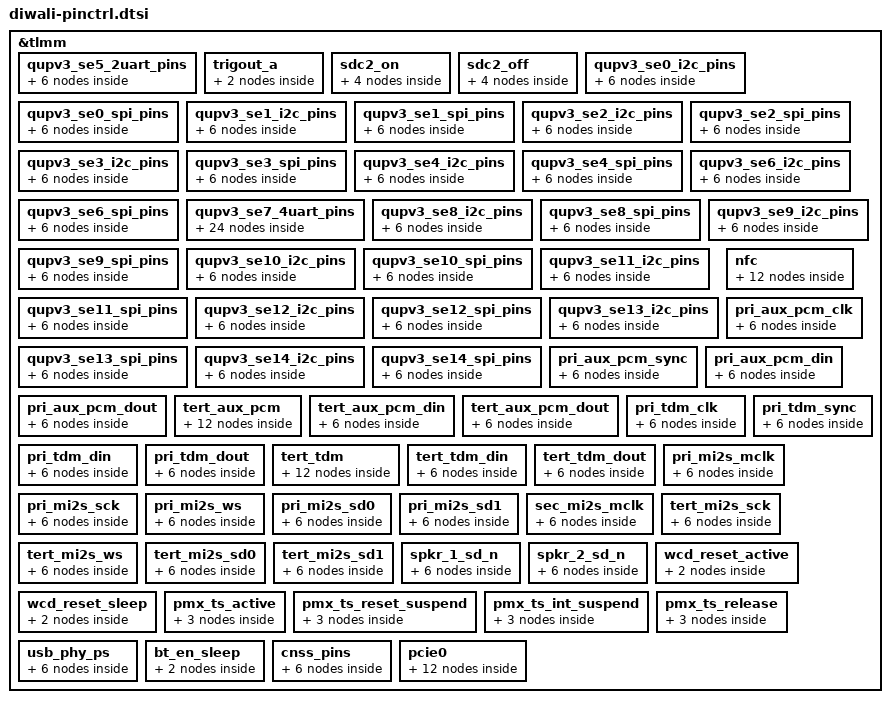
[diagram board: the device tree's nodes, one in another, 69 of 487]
&tlmm {
	qupv3_se5_2uart_pins: qupv3_se5_2uart_pins {
		qupv3_se5_2uart_active: qupv3_se5_2uart_active {
			mux {
				pins = "gpio22", "gpio23";
				function = "qup0_se5";
			};

			config {
				pins = "gpio22", "gpio23";
				drive-strength = <2>;
				bias-disable;
			};
		};

	qupv3_se5_2uart_sleep: qupv3_se5_2uart_sleep {
			mux {
				pins = "gpio22", "gpio23";
				function = "gpio";
			};

			config {
				pins = "gpio22", "gpio23";
				drive-strength = <2>;
				bias-pull-down;
			};
		};
	};

	trigout_a: trigout_a {
		mux {
			pins = "gpio52";
			function = "qdss_cti";
		};

		config {
			pins = "gpio52";
			drive-strength = <2>;
			bias-disable;
		};
	};

	sdc2_on: sdc2_on {
		clk {
			pins = "sdc2_clk";
			bias-disable;
			drive-strength = <16>;
		};

		cmd {
			pins = "sdc2_cmd";
			bias-pull-up;
			drive-strength = <10>;
		};

		data {
			pins = "sdc2_data";
			bias-pull-up;
			drive-strength = <10>;
		};

		sd-cd {
			pins = "gpio19";
			bias-pull-up;
			drive-strength = <2>;
		};
	};

	sdc2_off: sdc2_off {
		clk {
			pins = "sdc2_clk";
			bias-disable;
			drive-strength = <2>;
		};

		cmd {
			pins = "sdc2_cmd";
			bias-pull-up;
			drive-strength = <2>;
		};

		data {
			pins = "sdc2_data";
			bias-pull-up;
			drive-strength = <2>;
		};

		sd-cd {
			pins = "gpio19";
			bias-pull-up;
			drive-strength = <2>;
		};
	};

	qupv3_se0_i2c_pins: qupv3_se0_i2c_pins {
		qupv3_se0_i2c_active: qupv3_se0_i2c_active {
			mux {
				pins = "gpio0", "gpio1";
				function = "qup0_se0";
			};

			config {
				pins = "gpio0", "gpio1";
				drive-strength = <2>;
				bias-pull-up;
			};
		};

		qupv3_se0_i2c_sleep: qupv3_se0_i2c_sleep {
			mux {
				pins = "gpio0", "gpio1";
				function = "gpio";
			};

			config {
				pins = "gpio0", "gpio1";
				drive-strength = <2>;
				bias-disable;
			};
		};
	};

	qupv3_se0_spi_pins: qupv3_se0_spi_pins {
		qupv3_se0_spi_active: qupv3_se0_spi_active {
			mux {
				pins = "gpio0", "gpio1",
						"gpio2", "gpio3";
				function = "qup0_se0";
			};

			config {
				pins = "gpio0", "gpio1",
						"gpio2", "gpio3";
				drive-strength = <6>;
				bias-disable;
			};
		};

		qupv3_se0_spi_sleep: qupv3_se0_spi_sleep {
			mux {
				pins = "gpio0", "gpio1",
						"gpio2", "gpio3";
				function = "gpio";
			};

			config {
				pins = "gpio0", "gpio1",
						"gpio2", "gpio3";
				drive-strength = <6>;
				bias-disable;
			};
		};
	};

	qupv3_se1_i2c_pins: qupv3_se1_i2c_pins {
		qupv3_se1_i2c_active: qupv3_se1_i2c_active {
			mux {
				pins = "gpio4", "gpio5";
				function = "qup0_se1";
			};

			config {
				pins = "gpio4", "gpio5";
				drive-strength = <2>;
				bias-pull-up;
			};
		};

		qupv3_se1_i2c_sleep: qupv3_se1_i2c_sleep {
			mux {
				pins = "gpio4", "gpio5";
				function = "gpio";
			};

			config {
				pins = "gpio4", "gpio5";
				drive-strength = <2>;
				bias-disable;
			};
		};
	};

	qupv3_se1_spi_pins: qupv3_se1_spi_pins {
		qupv3_se1_spi_active: qupv3_se1_spi_active {
			mux {
				pins = "gpio4", "gpio5",
						"gpio6", "gpio7";
				function = "qup0_se1";
			};

			config {
				pins = "gpio4", "gpio5",
						"gpio6", "gpio7";
				drive-strength = <6>;
				bias-disable;
			};
		};

		qupv3_se1_spi_sleep: qupv3_se1_spi_sleep {
			mux {
				pins = "gpio4", "gpio5",
						"gpio6", "gpio7";
				function = "gpio";
			};

			config {
				pins = "gpio4", "gpio5",
						"gpio6", "gpio7";
				drive-strength = <6>;
				bias-disable;
			};
		};
	};

	qupv3_se2_i2c_pins: qupv3_se2_i2c_pins {
		qupv3_se2_i2c_active: qupv3_se2_i2c_active {
			mux {
				pins = "gpio8", "gpio9";
				function = "qup0_se2";
			};

			config {
				pins = "gpio8", "gpio9";
				drive-strength = <2>;
				bias-pull-up;
			};
		};

		qupv3_se2_i2c_sleep: qupv3_se2_i2c_sleep {
			mux {
				pins = "gpio8", "gpio9";
				function = "gpio";
			};

			config {
				pins = "gpio8", "gpio9";
				drive-strength = <2>;
				bias-disable;
			};
		};
	};

	qupv3_se2_spi_pins: qupv3_se2_spi_pins {
		qupv3_se2_spi_active: qupv3_se2_spi_active {
			mux {
				pins = "gpio8", "gpio9",
						"gpio10", "gpio11";
				function = "qup0_se2";
			};

			config {
				pins = "gpio8", "gpio9",
						"gpio10", "gpio11";
				drive-strength = <6>;
				bias-disable;
			};
		};

		qupv3_se2_spi_sleep: qupv3_se2_spi_sleep {
			mux {
				pins = "gpio8", "gpio9",
						"gpio10", "gpio11";
				function = "gpio";
			};

			config {
				pins = "gpio8", "gpio9",
						"gpio10", "gpio11";
				drive-strength = <6>;
				bias-disable;
			};
		};
	};

	qupv3_se3_i2c_pins: qupv3_se3_i2c_pins {
		qupv3_se3_i2c_active: qupv3_se3_i2c_active {
			mux {
				pins = "gpio12", "gpio13";
				function = "qup0_se3";
			};

			config {
				pins = "gpio12", "gpio13";
				drive-strength = <2>;
				bias-pull-up;
			};
		};

		qupv3_se3_i2c_sleep: qupv3_se3_i2c_sleep {
			mux {
				pins = "gpio12", "gpio13";
				function = "gpio";
			};

			config {
				pins = "gpio12", "gpio13";
				drive-strength = <2>;
				bias-disable;
			};
		};
	};

	qupv3_se3_spi_pins: qupv3_se3_spi_pins {
		qupv3_se3_spi_active: qupv3_se3_spi_active {
			mux {
				pins = "gpio12", "gpio13",
						"gpio14", "gpio15";
				function = "qup0_se3";
			};

			config {
				pins = "gpio12", "gpio13",
						"gpio14", "gpio15";
				drive-strength = <6>;
				bias-disable;
			};
		};

		qupv3_se3_spi_sleep: qupv3_se3_spi_sleep {
			mux {
				pins = "gpio12", "gpio13",
						"gpio14", "gpio15";
				function = "gpio";
			};

			config {
				pins = "gpio12", "gpio13",
						"gpio14", "gpio15";
				drive-strength = <6>;
				bias-disable;
			};
		};
	};

	qupv3_se4_i2c_pins: qupv3_se4_i2c_pins {
		qupv3_se4_i2c_active: qupv3_se4_i2c_active {
			mux {
				pins = "gpio16", "gpio17";
				function = "qup0_se4";
			};

			config {
				pins = "gpio16", "gpio17";
				drive-strength = <2>;
				bias-pull-up;
			};
		};

		qupv3_se4_i2c_sleep: qupv3_se4_i2c_sleep {
			mux {
				pins = "gpio16", "gpio17";
				function = "gpio";
			};

			config {
				pins = "gpio16", "gpio17";
				drive-strength = <2>;
				bias-disable;
			};
		};
	};

	qupv3_se4_spi_pins: qupv3_se4_spi_pins {
		qupv3_se4_spi_active: qupv3_se4_spi_active {
			mux {
				pins = "gpio16", "gpio17",
						"gpio18", "gpio19";
				function = "qup0_se4";
			};

			config {
				pins = "gpio16", "gpio17",
						"gpio18", "gpio19";
				drive-strength = <6>;
				bias-disable;
			};
		};

		qupv3_se4_spi_sleep: qupv3_se4_spi_sleep {
			mux {
				pins = "gpio16", "gpio17",
						"gpio18", "gpio19";
				function = "gpio";
			};

			config {
				pins = "gpio16", "gpio17",
						"gpio18", "gpio19";
				drive-strength = <6>;
				bias-disable;
			};
		};
	};

	qupv3_se6_i2c_pins: qupv3_se6_i2c_pins {
		qupv3_se6_i2c_active: qupv3_se6_i2c_active {
			mux {
				pins = "gpio24", "gpio25";
				function = "qup0_se6";
			};

			config {
				pins = "gpio24", "gpio25";
				drive-strength = <2>;
				bias-pull-up;
			};
		};

		qupv3_se6_i2c_sleep: qupv3_se6_i2c_sleep {
			mux {
				pins = "gpio24", "gpio25";
				function = "gpio";
			};

			config {
				pins = "gpio24", "gpio25";
				drive-strength = <2>;
				bias-disable;
			};
		};
	};

	qupv3_se6_spi_pins: qupv3_se6_spi_pins {
		qupv3_se6_spi_active: qupv3_se6_spi_active {
			mux {
				pins = "gpio24", "gpio25",
						"gpio26", "gpio27";
				function = "qup0_se6";
			};

			config {
				pins = "gpio24", "gpio25",
						"gpio26", "gpio27";
				drive-strength = <6>;
				bias-disable;
			};
		};

		qupv3_se6_spi_sleep: qupv3_se6_spi_sleep {
			mux {
				pins = "gpio24", "gpio25",
						"gpio26", "gpio27";
				function = "gpio";
			};

			config {
				pins = "gpio24", "gpio25",
						"gpio26", "gpio27";
				drive-strength = <6>;
				bias-disable;
			};
		};
	};

	qupv3_se7_4uart_pins: qupv3_se7_4uart_pins {
		qupv3_se7_default_cts:
				qupv3_se7_default_cts {
			mux {
				pins = "gpio28";
				function = "gpio";
			};

			config {
				pins = "gpio28";
				drive-strength = <2>;
				bias-disable;
			};
		};

		qupv3_se7_default_rtsrx:
			qupv3_se7_default_rtsrx {
			mux {
				pins = "gpio29", "gpio31";
				function = "gpio";
			};

			config {
				pins = "gpio29", "gpio31";
				drive-strength = <2>;
				bias-pull-down;
			};
		};

		qupv3_se7_default_tx:
			qupv3_se7_default_tx {
			mux {
				pins = "gpio30";
				function = "gpio";
			};

			config {
				pins = "gpio30";
				drive-strength = <2>;
				bias-pull-up;
			};
		};

		qupv3_se7_cts: qupv3_se7_cts {
			mux {
				pins = "gpio28";
				function = "qup0_se7";
			};

			config {
				pins = "gpio28";
				drive-strength = <2>;
				bias-disable;
			};
		};

		qupv3_se7_rts: qupv3_se7_rts {
			mux {
				pins = "gpio29";
				function = "qup0_se7";
			};

			config {
				pins = "gpio29";
				drive-strength = <2>;
				bias-pull-down;
			};
		};

		qupv3_se7_tx: qupv3_se7_tx {
			mux {
				pins = "gpio30";
				function = "qup0_se7";
			};

			config {
				pins = "gpio30";
				drive-strength = <2>;
				bias-pull-up;
			};
		};

		/* RX to be in gpio mode for sleep config */
		qupv3_se7_rx_wake: qupv3_se7_rx_wake {
			mux {
				pins = "gpio31";
				function = "gpio";
			};

			config {
				pins = "gpio31";
				drive-strength = <2>;
				bias-disable;
			};
		};

		qupv3_se7_rx_active: qupv3_se7_rx_active {
			mux {
				pins = "gpio31";
				function = "qup0_se7";
			};

			config {
				pins = "gpio31";
				drive-strength = <2>;
				bias-disable;
			};
		};
	};

	qupv3_se8_i2c_pins: qupv3_se8_i2c_pins {
		qupv3_se8_i2c_active: qupv3_se8_i2c_active {
			mux {
				pins = "gpio32", "gpio33";
				function = "qup1_se0";
			};

			config {
				pins = "gpio32", "gpio33";
				drive-strength = <2>;
				bias-pull-up;
			};
		};

		qupv3_se8_i2c_sleep: qupv3_se8_i2c_sleep {
			mux {
				pins = "gpio32", "gpio33";
				function = "gpio";
			};

			config {
				pins = "gpio32", "gpio33";
				drive-strength = <2>;
				bias-disable;
			};
		};
	};

	qupv3_se8_spi_pins: qupv3_se8_spi_pins {
		qupv3_se8_spi_active: qupv3_se8_spi_active {
			mux {
				pins = "gpio32", "gpio33",
						"gpio34", "gpio35";
				function = "qup1_se0";
			};

			config {
				pins = "gpio32", "gpio33",
						"gpio34", "gpio35";
				drive-strength = <6>;
				bias-disable;
			};
		};

		qupv3_se8_spi_sleep: qupv3_se8_spi_sleep {
			mux {
				pins = "gpio32", "gpio33",
						"gpio34", "gpio35";
				function = "gpio";
			};

			config {
				pins = "gpio32", "gpio33",
						"gpio34", "gpio35";
				drive-strength = <6>;
				bias-disable;
			};
		};
	};

	qupv3_se9_i2c_pins: qupv3_se9_i2c_pins {
		qupv3_se9_i2c_active: qupv3_se9_i2c_active {
			mux {
				pins = "gpio36", "gpio37";
				function = "qup1_se1";
			};

			config {
				pins = "gpio36", "gpio37";
				drive-strength = <2>;
				bias-pull-up;
			};
		};

		qupv3_se9_i2c_sleep: qupv3_se9_i2c_sleep {
			mux {
				pins = "gpio36", "gpio37";
				function = "gpio";
			};

			config {
				pins = "gpio36", "gpio37";
				drive-strength = <2>;
				bias-disable;
			};
		};
	};

	qupv3_se9_spi_pins: qupv3_se9_spi_pins {
		qupv3_se9_spi_active: qupv3_se9_spi_active {
			mux {
				pins = "gpio36", "gpio37",
						"gpio38", "gpio39";
				function = "qup1_se1";
			};

			config {
				pins = "gpio36", "gpio37",
						"gpio38", "gpio39";
				drive-strength = <6>;
				bias-disable;
			};
		};

		qupv3_se9_spi_sleep: qupv3_se9_spi_sleep {
			mux {
				pins = "gpio36", "gpio37",
						"gpio38", "gpio39";
				function = "gpio";
			};

			config {
				pins = "gpio36", "gpio37",
						"gpio38", "gpio39";
				drive-strength = <6>;
				bias-disable;
			};
		};
	};

	qupv3_se10_i2c_pins: qupv3_se10_i2c_pins {
		qupv3_se10_i2c_active: qupv3_se10_i2c_active {
			mux {
				pins = "gpio40", "gpio41";
				function = "qup1_se2";
			};

			config {
				pins = "gpio40", "gpio41";
				drive-strength = <2>;
				bias-pull-up;
			};
		};

		qupv3_se10_i2c_sleep: qupv3_se10_i2c_sleep {
			mux {
				pins = "gpio40", "gpio41";
				function = "gpio";
			};

			config {
				pins = "gpio40", "gpio41";
				drive-strength = <2>;
				bias-disable;
			};
		};
	};

	qupv3_se10_spi_pins: qupv3_se10_spi_pins {
		qupv3_se10_spi_active: qupv3_se10_spi_active {
			mux {
				pins = "gpio40", "gpio41",
						"gpio42", "gpio43";
				function = "qup1_se2";
			};

			config {
				pins = "gpio40", "gpio41",
						"gpio42", "gpio43";
				drive-strength = <6>;
				bias-disable;
			};
		};

		qupv3_se10_spi_sleep: qupv3_se10_spi_sleep {
			mux {
				pins = "gpio40", "gpio41",
						"gpio42", "gpio43";
				function = "gpio";
			};

			config {
				pins = "gpio40", "gpio41",
						"gpio42", "gpio43";
				drive-strength = <6>;
				bias-disable;
			};
		};
	};

	qupv3_se11_i2c_pins: qupv3_se11_i2c_pins {
		qupv3_se11_i2c_active: qupv3_se11_i2c_active {
			mux {
				pins = "gpio44", "gpio45";
				function = "qup1_se3";
			};

			config {
				pins = "gpio44", "gpio45";
				drive-strength = <2>;
				bias-pull-up;
			};
		};

		qupv3_se11_i2c_sleep: qupv3_se11_i2c_sleep {
			mux {
				pins = "gpio44", "gpio45";
				function = "gpio";
			};

			config {
				pins = "gpio44", "gpio45";
				drive-strength = <2>;
				bias-disable;
			};
		};
	};

	qupv3_se11_spi_pins: qupv3_se11_spi_pins {
		qupv3_se11_spi_active: qupv3_se11_spi_active {
			mux {
				pins = "gpio44", "gpio45",
						"gpio46", "gpio47";
				function = "qup1_se3";
			};

			config {
				pins = "gpio44", "gpio45",
						"gpio46", "gpio47";
				drive-strength = <6>;
				bias-disable;
			};
		};

		qupv3_se11_spi_sleep: qupv3_se11_spi_sleep {
			mux {
				pins = "gpio44", "gpio45",
						"gpio46", "gpio47";
				function = "gpio";
			};

			config {
				pins = "gpio44", "gpio45",
						"gpio46", "gpio47";
				drive-strength = <6>;
				bias-disable;
			};
		};
	};

	qupv3_se12_i2c_pins: qupv3_se12_i2c_pins {
		qupv3_se12_i2c_active: qupv3_se12_i2c_active {
			mux {
				pins = "gpio48", "gpio49";
				function = "qup1_se4";
			};

			config {
				pins = "gpio48", "gpio49";
				drive-strength = <2>;
				bias-pull-up;
			};
		};

		qupv3_se12_i2c_sleep: qupv3_se12_i2c_sleep {
			mux {
				pins = "gpio48", "gpio49";
				function = "gpio";
			};

			config {
				pins = "gpio48", "gpio49";
				drive-strength = <2>;
				bias-disable;
			};
		};
	};

	qupv3_se12_spi_pins: qupv3_se12_spi_pins {
		qupv3_se12_spi_active: qupv3_se12_spi_active {
			mux {
				pins = "gpio48", "gpio49",
						"gpio50", "gpio51";
				function = "qup1_se4";
			};

			config {
				pins = "gpio48", "gpio49",
						"gpio50", "gpio51";
				drive-strength = <6>;
				bias-disable;
			};
		};

		qupv3_se12_spi_sleep: qupv3_se12_spi_sleep {
			mux {
				pins = "gpio48", "gpio49",
						"gpio50", "gpio51";
				function = "gpio";
			};

			config {
				pins = "gpio48", "gpio49",
						"gpio50", "gpio51";
				drive-strength = <6>;
				bias-disable;
			};
		};
	};

	qupv3_se13_i2c_pins: qupv3_se13_i2c_pins {
		qupv3_se13_i2c_active: qupv3_se13_i2c_active {
			mux {
				pins = "gpio52", "gpio53";
				function = "qup1_se5";
			};

			config {
				pins = "gpio52", "gpio53";
				drive-strength = <2>;
				bias-pull-up;
			};
		};

		qupv3_se13_i2c_sleep: qupv3_se13_i2c_sleep {
			mux {
				pins = "gpio52", "gpio53";
				function = "gpio";
			};

			config {
				pins = "gpio52", "gpio53";
				drive-strength = <2>;
				bias-disable;
			};
		};
	};

	qupv3_se13_spi_pins: qupv3_se13_spi_pins {
		qupv3_se13_spi_active: qupv3_se13_spi_active {
			mux {
				pins = "gpio52", "gpio53",
						"gpio54", "gpio55";
				function = "qup1_se5";
			};

			config {
				pins = "gpio52", "gpio53",
						"gpio54", "gpio55";
				drive-strength = <6>;
				bias-disable;
			};
		};

		qupv3_se13_spi_sleep: qupv3_se13_spi_sleep {
			mux {
				pins = "gpio52", "gpio53",
						"gpio54", "gpio55";
				function = "gpio";
			};

			config {
				pins = "gpio52", "gpio53",
						"gpio54", "gpio55";
				drive-strength = <6>;
				bias-disable;
			};
		};
	};

	qupv3_se14_i2c_pins: qupv3_se14_i2c_pins {
		qupv3_se14_i2c_active: qupv3_se14_i2c_active {
			mux {
				pins = "gpio56", "gpio57";
				function = "qup1_se6";
			};

			config {
				pins = "gpio56", "gpio57";
				drive-strength = <2>;
				bias-pull-up;
			};
		};

		qupv3_se14_i2c_sleep: qupv3_se14_i2c_sleep {
			mux {
				pins = "gpio56", "gpio57";
				function = "gpio";
			};

			config {
				pins = "gpio56", "gpio57";
				drive-strength = <2>;
				bias-disable;
			};
		};
	};

	qupv3_se14_spi_pins: qupv3_se14_spi_pins {
		qupv3_se14_spi_active: qupv3_se14_spi_active {
			mux {
				pins = "gpio56", "gpio57",
						"gpio58", "gpio59";
				function = "qup1_se6";
			};

			config {
				pins = "gpio56", "gpio57",
						"gpio58", "gpio59";
				drive-strength = <6>;
				bias-disable;
			};
		};

		qupv3_se14_spi_sleep: qupv3_se14_spi_sleep {
			mux {
				pins = "gpio56", "gpio57",
						"gpio58", "gpio59";
				function = "gpio";
			};

			config {
				pins = "gpio56", "gpio57",
						"gpio58", "gpio59";
				drive-strength = <6>;
				bias-disable;
			};
		};
	};

	nfc {
		nfc_int_active: nfc_int_active {
			/* active state */
			mux {
				/* NFC Read Interrupt */
				pins = "gpio41";
				function = "gpio";
			};

			config {
				pins = "gpio41";
				drive-strength = <2>;
				bias-pull-down;
			};
		};

		nfc_int_suspend: nfc_int_suspend {
		/* sleep state */
			mux {
				/* NFC Read Interrupt */
				pins = "gpio41";
				function = "gpio";
			};

			config {
				pins = "gpio41";
				drive-strength = <2>;
				bias-pull-down;
			};
		};

		nfc_enable_active: nfc_enable_active {
			mux {
				/* Enable, Firmware and Clock request gpios */
				pins = "gpio38", "gpio40", "gpio39";
				function = "gpio";
			};

			config {
				pins = "gpio38", "gpio40", "gpio39";
				drive-strength = <2>;
				bias-disable;
			};
		};

		nfc_enable_suspend: nfc_enable_suspend {
			mux {
				pins = "gpio38", "gpio40", "gpio39";
				function = "gpio";
			};

			config {
				pins = "gpio38", "gpio40", "gpio39";
				drive-strength = <2>;
				bias-disable;
			};
		};
	};

	pri_aux_pcm_clk {
		pri_aux_pcm_clk_sleep: pri_aux_pcm_clk_sleep {
			mux {
				pins = "gpio127";
				function = "gpio";
			};

			config {
				pins = "gpio127";
				drive-strength = <2>;   /* 2 mA */
				bias-pull-down;         /* PULL DOWN */
				input-enable;
			};
		};

		pri_aux_pcm_clk_active: pri_aux_pcm_clk_active {
			mux {
				pins = "gpio127";
				function = "mi2s0_sck";
			};

			config {
				pins = "gpio127";
				drive-strength = <8>;   /* 8 mA */
				bias-disable;           /* NO PULL */
				output-high;
			};
		};
	};

	pri_aux_pcm_sync {
		pri_aux_pcm_sync_sleep: pri_aux_pcm_sync_sleep {
			mux {
				pins = "gpio130";
				function = "gpio";
			};

			config {
				pins = "gpio130";
				drive-strength = <2>;   /* 2 mA */
				bias-pull-down;         /* PULL DOWN */
				input-enable;
			};
		};

		pri_aux_pcm_sync_active: pri_aux_pcm_sync_active {
			mux {
				pins = "gpio130";
				function = "mi2s0_ws";
			};

			config {
				pins = "gpio130";
				drive-strength = <8>;   /* 8 mA */
				bias-disable;           /* NO PULL */
				output-high;
			};
		};
	};

	pri_aux_pcm_din {
		pri_aux_pcm_din_sleep: pri_aux_pcm_din_sleep {
			mux {
				pins = "gpio128";
				function = "gpio";
			};

			config {
				pins = "gpio128";
				drive-strength = <2>;   /* 2 mA */
				bias-pull-down;         /* PULL DOWN */
				input-enable;
			};
		};

		pri_aux_pcm_din_active: pri_aux_pcm_din_active {
			mux {
				pins = "gpio128";
				function = "mi2s0_data0";
			};

			config {
				pins = "gpio128";
				drive-strength = <8>;   /* 8 mA */
				bias-disable;           /* NO PULL */
			};
		};
	};

	pri_aux_pcm_dout {
		pri_aux_pcm_dout_sleep: pri_aux_pcm_dout_sleep {
			mux {
				pins = "gpio129";
				function = "gpio";
			};

			config {
				pins = "gpio129";
				drive-strength = <2>;   /* 2 mA */
				bias-pull-down;         /* PULL DOWN */
				input-enable;
			};
		};

		pri_aux_pcm_dout_active: pri_aux_pcm_dout_active {
			mux {
				pins = "gpio129";
				function = "mi2s0_data1";
			};

			config {
				pins = "gpio129";
				drive-strength = <8>;   /* 8 mA */
				bias-disable;           /* NO PULL */
			};
		};
	};

	tert_aux_pcm {
		tert_aux_pcm_clk_sleep: tert_aux_pcm_clk_sleep {
			mux {
				pins = "gpio60";
				function = "gpio";
			};

			config {
				pins = "gpio60";
				drive-strength = <2>;   /* 2 mA */
				bias-pull-down;         /* PULL DOWN */
				input-enable;
			};
		};

		tert_aux_pcm_clk_active: tert_aux_pcm_clk_active {
			mux {
				pins = "gpio60";
				function = "mi2s2_sck";
			};

			config {
				pins = "gpio60";
				drive-strength = <8>;   /* 8 mA */
				bias-disable;           /* NO PULL */
				output-high;
			};
		};

		tert_aux_pcm_ws_sleep: tert_aux_pcm_ws_sleep {
			mux {
				pins = "gpio62";
				function = "gpio";
			};

			config {
				pins = "gpio62";
				drive-strength = <2>;   /* 2 mA */
				bias-pull-down;         /* PULL DOWN */
				input-enable;
			};
		};

		tert_aux_pcm_ws_active: tert_aux_pcm_ws_active {
			mux {
				pins = "gpio62";
				function = "mi2s2_ws";
			};

			config {
				pins = "gpio62";
				drive-strength = <8>;   /* 8 mA */
				bias-disable;           /* NO PULL */
				output-high;
			};
		};
	};

	tert_aux_pcm_din {
		tert_aux_pcm_din_sleep: tert_aux_pcm_din_sleep {
			mux {
				pins = "gpio61";
				function = "gpio";
			};

			config {
				pins = "gpio61";
				drive-strength = <2>;   /* 2 mA */
				bias-pull-down;         /* PULL DOWN */
				input-enable;
			};
		};

		tert_aux_pcm_din_active: tert_aux_pcm_din_active {
			mux {
				pins = "gpio61";
				function = "mi2s2_data0";
			};

			config {
				pins = "gpio61";
				drive-strength = <8>;   /* 8 mA */
				bias-disable;           /* NO PULL */
			};
		};
	};

	tert_aux_pcm_dout {
		tert_aux_pcm_dout_sleep: tert_aux_pcm_dout_sleep {
			mux {
				pins = "gpio63";
				function = "gpio";
			};

			config {
				pins = "gpio63";
				drive-strength = <2>;   /* 2 mA */
				bias-pull-down;         /* PULL DOWN */
				input-enable;
			};
		};

		tert_aux_pcm_dout_active: tert_aux_pcm_dout_active {
			mux {
				pins = "gpio63";
				function = "mi2s2_data1";
			};

			config {
				pins = "gpio63";
				drive-strength = <8>;   /* 8 mA */
				bias-disable;           /* NO PULL */
			};
		};
	};

	pri_tdm_clk {
		pri_tdm_clk_sleep: pri_tdm_clk_sleep {
			mux {
				pins = "gpio127";
				function = "gpio";
			};

			config {
				pins = "gpio127";
				drive-strength = <2>;   /* 2 mA */
				bias-pull-down;         /* PULL DOWN */
				input-enable;
			};
		};

		pri_tdm_clk_active: pri_tdm_clk_active {
			mux {
				pins = "gpio127";
				function = "mi2s0_sck";
			};

			config {
				pins = "gpio127";
				drive-strength = <8>;   /* 8 mA */
				bias-disable;           /* NO PULL */
				output-high;
			};
		};
	};

	pri_tdm_sync {
		pri_tdm_sync_sleep: pri_tdm_sync_sleep {
			mux {
				pins = "gpio130";
				function = "gpio";
			};

			config {
				pins = "gpio130";
				drive-strength = <2>;   /* 2 mA */
				bias-pull-down;         /* PULL DOWN */
				input-enable;
			};
		};

		pri_tdm_sync_active: pri_tdm_sync_active {
			mux {
				pins = "gpio130";
				function = "mi2s0_ws";
			};

			config {
				pins = "gpio130";
				drive-strength = <8>;   /* 8 mA */
				bias-disable;           /* NO PULL */
				output-high;
			};
		};
	};

	pri_tdm_din {
		pri_tdm_din_sleep: pri_tdm_din_sleep {
			mux {
				pins = "gpio128";
				function = "gpio";
			};

			config {
				pins = "gpio128";
				drive-strength = <2>;   /* 2 mA */
				bias-pull-down;         /* PULL DOWN */
				input-enable;
			};
		};

		pri_tdm_din_active: pri_tdm_din_active {
			mux {
				pins = "gpio128";
				function = "mi2s0_data0";
			};

			config {
				pins = "gpio128";
				drive-strength = <8>;   /* 8 mA */
				bias-disable;           /* NO PULL */
			};
		};
	};

	pri_tdm_dout {
		pri_tdm_dout_sleep: pri_tdm_dout_sleep {
			mux {
				pins = "gpio129";
				function = "gpio";
			};

			config {
				pins = "gpio129";
				drive-strength = <2>;   /* 2 mA */
				bias-pull-down;         /* PULL DOWN */
				input-enable;
			};
		};

		pri_tdm_dout_active: pri_tdm_dout_active {
			mux {
				pins = "gpio129";
				function = "mi2s0_data1";
			};

			config {
				pins = "gpio129";
				drive-strength = <8>;   /* 8 mA */
				bias-disable;           /* NO PULL */
			};
		};
	};

	tert_tdm {
		tert_tdm_clk_sleep: tert_tdm_clk_sleep {
			mux {
				pins = "gpio60";
				function = "gpio";
			};

			config {
				pins = "gpio60";
				drive-strength = <2>;   /* 2 mA */
				bias-pull-down;         /* PULL DOWN */
				input-enable;
			};
		};

		tert_tdm_clk_active: tert_tdm_clk_active {
			mux {
				pins = "gpio60";
				function = "mi2s2_sck";
			};

			config {
				pins = "gpio60";
				drive-strength = <8>;   /* 8 mA */
				bias-disable;           /* NO PULL */
				output-high;
			};
		};

		tert_tdm_ws_sleep: tert_tdm_ws_sleep {
			mux {
				pins = "gpio62";
				function = "gpio";
			};

			config {
				pins = "gpio62";
				drive-strength = <2>;   /* 2 mA */
				bias-pull-down;         /* PULL DOWN */
				input-enable;
			};
		};

		tert_tdm_ws_active: tert_tdm_ws_active {
			mux {
				pins = "gpio62";
				function = "mi2s2_ws";
			};

			config {
				pins = "gpio62";
				drive-strength = <8>;   /* 8 mA */
				bias-disable;           /* NO PULL */
				output-high;
			};
		};
	};

	tert_tdm_din {
		tert_tdm_din_sleep: tert_tdm_din_sleep {
			mux {
				pins = "gpio61";
				function = "gpio";
			};

			config {
				pins = "gpio61";
				drive-strength = <2>;   /* 2 mA */
				bias-pull-down;         /* PULL DOWN */
				input-enable;
			};
		};

		tert_tdm_din_active: tert_tdm_din_active {
			mux {
				pins = "gpio61";
				function = "mi2s2_data0";
			};

			config {
				pins = "gpio61";
				drive-strength = <8>;   /* 8 mA */
				bias-disable;           /* NO PULL */
			};
		};
	};

	tert_tdm_dout {
		tert_tdm_dout_sleep: tert_tdm_dout_sleep {
			mux {
				pins = "gpio63";
				function = "gpio";
			};

			config {
				pins = "gpio63";
				drive-strength = <2>;   /* 2 mA */
				bias-pull-down;         /* PULL DOWN */
				input-enable;
			};
		};

		tert_tdm_dout_active: tert_tdm_dout_active {
			mux {
				pins = "gpio63";
				function = "mi2s2_data1";
			};

			config {
				pins = "gpio63";
				drive-strength = <8>;   /* 8 mA */
				bias-disable;           /* NO PULL */
			};
		};
	};

	pri_mi2s_mclk {
		pri_mi2s_mclk_sleep: pri_mi2s_mclk_sleep {
			mux {
				pins = "gpio126";
				function = "gpio";
			};

			config {
				pins = "gpio126";
				drive-strength = <2>;   /* 2 mA */
				bias-pull-down;         /* PULL DOWN */
				input-enable;
			};
		};

		pri_mi2s_mclk_active: pri_mi2s_mclk_active {
			mux {
				pins = "gpio126";
				function = "mi2s_mclk0";
			};

			config {
				pins = "gpio126";
				drive-strength = <8>;   /* 8 mA */
				bias-disable;           /* NO PULL */
				output-high;
			};
		};
	};

	pri_mi2s_sck {
		pri_mi2s_sck_sleep: pri_mi2s_sck_sleep {
			mux {
				pins = "gpio127";
				function = "gpio";
			};

			config {
				pins = "gpio127";
				drive-strength = <2>;   /* 2 mA */
				bias-pull-down;         /* PULL DOWN */
				input-enable;
			};
		};

		pri_mi2s_sck_active: pri_mi2s_sck_active {
			mux {
				pins = "gpio127";
				function = "mi2s0_sck";
			};

			config {
				pins = "gpio127";
				drive-strength = <8>;   /* 8 mA */
				bias-disable;           /* NO PULL */
				output-high;
			};
		};
	};

	pri_mi2s_ws {
		pri_mi2s_ws_sleep: pri_mi2s_ws_sleep {
			mux {
				pins = "gpio130";
				function = "gpio";
			};

			config {
				pins = "gpio130";
				drive-strength = <2>;   /* 2 mA */
				bias-pull-down;         /* PULL DOWN */
				input-enable;
			};
		};

		pri_mi2s_ws_active: pri_mi2s_ws_active {
			mux {
				pins = "gpio130";
				function = "mi2s0_ws";
			};

			config {
				pins = "gpio130";
				drive-strength = <8>;   /* 8 mA */
				bias-disable;           /* NO PULL */
				output-high;
			};
		};
	};

	pri_mi2s_sd0 {
		pri_mi2s_sd0_sleep: pri_mi2s_sd0_sleep {
			mux {
				pins = "gpio128";
				function = "gpio";
			};

			config {
				pins = "gpio128";
				drive-strength = <2>;   /* 2 mA */
				bias-pull-down;         /* PULL DOWN */
				input-enable;
			};
		};

		pri_mi2s_sd0_active: pri_mi2s_sd0_active {
			mux {
				pins = "gpio128";
				function = "mi2s0_data0";
			};

			config {
				pins = "gpio128";
				drive-strength = <8>;   /* 8 mA */
				bias-disable;           /* NO PULL */
				output-high;
			};
		};
	};

	pri_mi2s_sd1 {
		pri_mi2s_sd1_sleep: pri_mi2s_sd1_sleep {
			mux {
				pins = "gpio129";
				function = "gpio";
			};

			config {
				pins = "gpio129";
				drive-strength = <2>;   /* 2 mA */
				bias-pull-down;         /* PULL DOWN */
				input-enable;
			};
		};

		pri_mi2s_sd1_active: pri_mi2s_sd1_active {
			mux {
				pins = "gpio129";
				function = "mi2s0_data1";
			};

			config {
				pins = "gpio129";
				drive-strength = <8>;   /* 8 mA */
				bias-disable;           /* NO PULL */
				output-high;
			};
		};
	};

	sec_mi2s_mclk {
		sec_mi2s_mclk_sleep: sec_mi2s_mclk_sleep {
			mux {
				pins = "gpio125";
				function = "gpio";
			};

			config {
				pins = "gpio125";
				drive-strength = <2>;   /* 2 mA */
				bias-pull-down;         /* PULL DOWN */
				input-enable;
			};
		};

		sec_mi2s_mclk_active: sec_mi2s_mclk_active {
			mux {
				pins = "gpio124";
				function = "mi2s_mclk1";
			};

			config {
				pins = "gpio124";
				drive-strength = <8>;   /* 8 mA */
				bias-disable;           /* NO PULL */
				output-high;
			};
		};
	};

	tert_mi2s_sck {
		tert_mi2s_sck_sleep: tert_mi2s_sck_sleep {
			mux {
				pins = "gpio60";
				function = "gpio";
			};

			config {
				pins = "gpio60";
				drive-strength = <2>;   /* 2 mA */
				bias-pull-down;         /* PULL DOWN */
				input-enable;
			};
		};

		tert_mi2s_sck_active: tert_mi2s_sck_active {
			mux {
				pins = "gpio60";
				function = "mi2s2_sck";
			};

			config {
				pins = "gpio60";
				drive-strength = <8>;   /* 8 mA */
				bias-disable;           /* NO PULL */
			};
		};
	};

	tert_mi2s_ws {
		tert_mi2s_ws_sleep: tert_mi2s_ws_sleep {
			mux {
				pins = "gpio62";
				function = "gpio";
			};

			config {
				pins = "gpio62";
				drive-strength = <2>;   /* 2 mA */
				bias-pull-down;         /* PULL DOWN */
				input-enable;
			};
		};

		tert_mi2s_ws_active: tert_mi2s_ws_active {
			mux {
				pins = "gpio62";
				function = "mi2s2_ws";
			};

			config {
				pins = "gpio62";
				drive-strength = <8>;   /* 8 mA */
				bias-disable;           /* NO PULL */
			};
		};
	};

	tert_mi2s_sd0 {
		tert_mi2s_sd0_sleep: tert_mi2s_sd0_sleep {
			mux {
				pins = "gpio61";
				function = "gpio";
			};

			config {
				pins = "gpio61";
				drive-strength = <2>;   /* 2 mA */
				bias-pull-down;         /* PULL DOWN */
				input-enable;
			};
		};

		tert_mi2s_sd0_active: tert_mi2s_sd0_active {
			mux {
				pins = "gpio61";
				function = "mi2s2_data0";
			};

			config {
				pins = "gpio61";
				drive-strength = <8>;   /* 8 mA */
				bias-disable;           /* NO PULL */
			};
		};
	};

	tert_mi2s_sd1 {
		tert_mi2s_sd1_sleep: tert_mi2s_sd1_sleep {
			mux {
				pins = "gpio63";
				function = "gpio";
			};

			config {
				pins = "gpio63";
				drive-strength = <2>;   /* 2 mA */
				bias-pull-down;         /* PULL DOWN */
				input-enable;
			};
		};

		tert_mi2s_sd1_active: tert_mi2s_sd1_active {
			mux {
				pins = "gpio63";
				function = "mi2s2_data1";
			};

			config {
				pins = "gpio63";
				drive-strength = <8>;   /* 8 mA */
				bias-disable;           /* NO PULL */
			};
		};
	};

	/* WSA speaker reset pins */
	spkr_1_sd_n {
		spkr_1_sd_n_sleep: spkr_1_sd_n_sleep {
			mux {
				pins = "gpio50";
				function = "gpio";
			};

			config {
				pins = "gpio50";
				drive-strength = <2>;   /* 2 mA */
				bias-pull-down;
				input-enable;
			};
		};

		spkr_1_sd_n_active: spkr_1_sd_n_active {
			mux {
				pins = "gpio50";
				function = "gpio";
			};

			config {
				pins = "gpio50";
				drive-strength = <16>;   /* 16 mA */
				bias-disable;
				output-high;
			};
		};
	};

	spkr_2_sd_n {
		spkr_2_sd_n_sleep: spkr_2_sd_n_sleep {
			mux {
				pins = "gpio18";
				function = "gpio";
			};

			config {
				pins = "gpio18";
				drive-strength = <2>;   /* 2 mA */
				bias-pull-down;
				input-enable;
			};
		};

		spkr_2_sd_n_active: spkr_2_sd_n_active {
			mux {
				pins = "gpio18";
				function = "gpio";
			};

			config {
				pins = "gpio18";
				drive-strength = <16>;   /* 16 mA */
				bias-disable;
				output-high;
			};
		};
	};

	/* WCD reset pin */
	wcd_reset_active: wcd_reset_active {
		mux {
			pins = "gpio54";
			function = "gpio";
		};

		config {
			pins = "gpio54";
			drive-strength = <16>;
			output-high;
		};
	};

	wcd_reset_sleep: wcd_reset_sleep {
		mux {
			pins = "gpio54";
			function = "gpio";
		};

		config {
			pins = "gpio54";
			drive-strength = <16>;
			bias-disable;
		};
	};

	/* touchscreen pins */
	pmx_ts_active {
		ts_active: ts_active {
			mux {
				pins = "gpio46", "gpio51";
				function = "gpio";
			};

			config {
				pins = "gpio46", "gpio51";
				drive-strength = <8>;
				bias-pull-up;
			};
		};
	};

	pmx_ts_reset_suspend {
		ts_reset_suspend: ts_reset_suspend {
			mux {
				pins = "gpio46";
				function = "gpio";
			};

			config {
				pins = "gpio46";
				drive-strength = <2>;
				bias-pull-down;
			};
		};
	};

	pmx_ts_int_suspend {
		ts_int_suspend: ts_int_suspend {
			mux {
				pins = "gpio51";
				function = "gpio";
			};

			config {
				pins = "gpio51";
				drive-strength = <2>;
				bias-pull-down;
			};
		};
	};

	pmx_ts_release {
		ts_release: ts_release {
			mux {
				pins = "gpio46", "gpio51";
				function = "gpio";
			};

			config {
				pins = "gpio46", "gpio51";
				drive-strength = <2>;
				bias-disable;
			};
		};
	};

	usb_phy_ps: usb_phy_ps {
		usb3phy_portselect_default: usb3phy_portselect_default {
			mux {
				pins = "gpio143";
				function = "usb0_phy";
			};

			config {
				pins = "gpio143";
				bias-disable;
				drive-strength = <2>;
			};
		};

		usb3phy_portselect_gpio: usb3phy_portselect_gpio {
			mux {
				pins = "gpio143";
				function = "gpio";
			};

			config {
				pins = "gpio143";
				drive-strength = <2>;
				bias-disable;
				input-enable;
			};
		};
	};

	bt_en_sleep: bt_en_sleep {
		mux {
			pins = "gpio114";
			function = "gpio";
		};

		config {
			pins = "gpio114";
			drive-strength = <2>;
			output-low;
			bias-pull-down;
		};
	};

	cnss_pins {
		cnss_wlan_en_active: cnss_wlan_en_active {
			mux {
				pins = "gpio49";
				function = "gpio";
			};

			config {
				pins = "gpio49";
				drive-strength = <16>;
				output-high;
				bias-pull-up;
			};
		};

		cnss_wlan_en_sleep: cnss_wlan_en_sleep {
			mux {
				pins = "gpio49";
				function = "gpio";
			};

			config {
				pins = "gpio49";
				drive-strength = <2>;
				output-low;
				bias-pull-down;
			};
		};
	};

	pcie0 {
		pcie0_perst_default: pcie0_perst_default {
			mux {
				pins = "gpio117";
				function = "gpio";
			};

			config {
				pins = "gpio117";
				drive-strength = <2>;
				bias-pull-down;
			};
		};

		pcie0_clkreq_default: pcie0_clkreq_default {
			mux {
				pins = "gpio118";
				function = "pcie0_clk";
			};

			config {
				pins = "gpio118";
				drive-strength = <2>;
				bias-pull-up;
			};
		};

		pcie0_wake_default: pcie0_wake_default {
			mux {
				pins = "gpio119";
				function = "gpio";
			};

			config {
				pins = "gpio119";
				drive-strength = <2>;
				bias-pull-up;
			};
		};

		pcie0_clkreq_sleep: pcie0_clkreq_sleep {
			mux {
				pins = "gpio118";
				function = "gpio";
			};

			config {
				pins = "gpio118";
				drive-strength = <2>;
				bias-pull-up;
			};
		};

	};


};
